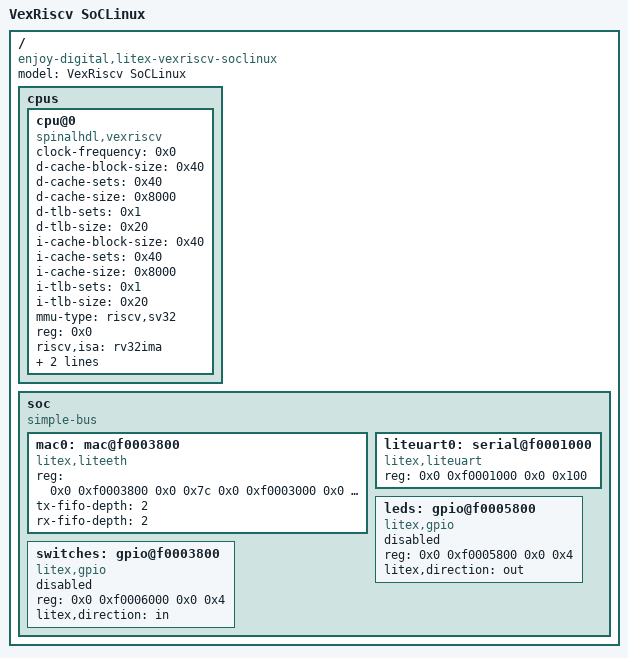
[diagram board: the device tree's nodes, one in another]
/dts-v1/;

/ {
	#address-cells = <0x2>;
	#size-cells = <0x2>;
	compatible = "enjoy-digital,litex-vexriscv-soclinux";
	model = "VexRiscv SoCLinux";

	cpus {
		#address-cells = <0x1>;
		#size-cells = <0x0>;

		cpu@0 {
			clock-frequency = <0x0>;
			compatible = "spinalhdl,vexriscv", "sifive,rocket0", "riscv";
			d-cache-block-size = <0x40>;
			d-cache-sets = <0x40>;
			d-cache-size = <0x8000>;
			d-tlb-sets = <0x1>;
			d-tlb-size = <0x20>;
			device_type = "cpu";
			i-cache-block-size = <0x40>;
			i-cache-sets = <0x40>;
			i-cache-size = <0x8000>;
			i-tlb-sets = <0x1>;
			i-tlb-size = <0x20>;
			mmu-type = "riscv,sv32";
			reg = <0x0>;
			riscv,isa = "rv32ima";
			sifive,itim = <0x1>;
			status = "okay";
			tlb-split;
		};
	};

	soc {
		#address-cells = <0x2>;
		#size-cells = <0x2>;
		compatible = "simple-bus";
		ranges;

		mac0: mac@f0003800 {
			compatible = "litex,liteeth";
			reg = <0x0 0xf0003800 0x0 0x7c
				0x0 0xf0003000 0x0 0x0a
				0x0 0xb0000000 0x0 0x2000>;
			tx-fifo-depth = <2>;
			rx-fifo-depth = <2>;
		};

		liteuart0: serial@f0001000 {
			device_type = "serial";
			compatible = "litex,liteuart";
			reg = <0x0 0xf0001000 0x0 0x100>;
			status = "okay";
		};

		leds: gpio@f0005800 {
			compatible = "litex,gpio";
			reg = <0x0 0xf0005800 0x0 0x4>;
			litex,direction = "out";
			status = "disabled";
		};

		switches: gpio@f0003800 {
			compatible = "litex,gpio";
			reg = <0x0 0xf0006000 0x0 0x4>;
			litex,direction = "in";
			status = "disabled";
		};
	};
};
